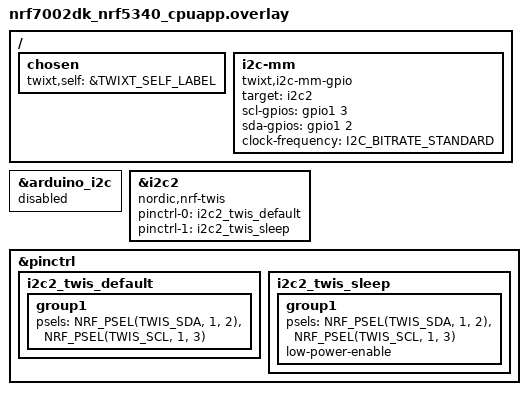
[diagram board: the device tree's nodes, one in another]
/*
 * Copyright (c) 2026 Christoph Jans <jans.christoph@gmail.com>
 *
 * SPDX-License-Identifier: Apache-2.0
 */

/* A board on an nRF7002 DK (-DMCU=b): the bus on the Arduino SDA P1.02, SCL P1.03, at the DK's
 * 1.8 V. TWIS2 is the target; the controller is software on the same pins (twixt,i2c-mm-gpio),
 * since the TWIM cannot detect lost arbitration. TWIM1 (arduino_i2c) has the same pins and is
 * off. The log is on the DK's VCOM.
 */

#include <zephyr/dt-bindings/i2c/i2c.h>

/ {
	chosen {
		twixt,self = &TWIXT_SELF_LABEL;
	};

	i2c-mm {
		compatible = "twixt,i2c-mm-gpio";
		target = <&i2c2>;
		scl-gpios = <&gpio1 3 0>;
		sda-gpios = <&gpio1 2 0>;
		clock-frequency = <I2C_BITRATE_STANDARD>;
		#address-cells = <1>;
		#size-cells = <0>;

#include "../twixt_mcus.dtsi"
	};
};

&arduino_i2c {
	status = "disabled";
};

&i2c2 {
	compatible = "nordic,nrf-twis";
	status = "okay";
	pinctrl-0 = <&i2c2_twis_default>;
	pinctrl-1 = <&i2c2_twis_sleep>;
	pinctrl-names = "default", "sleep";
};

&pinctrl {
	i2c2_twis_default: i2c2_twis_default {
		group1 {
			psels = <NRF_PSEL(TWIS_SDA, 1, 2)>,
				<NRF_PSEL(TWIS_SCL, 1, 3)>;
		};
	};

	i2c2_twis_sleep: i2c2_twis_sleep {
		group1 {
			psels = <NRF_PSEL(TWIS_SDA, 1, 2)>,
				<NRF_PSEL(TWIS_SCL, 1, 3)>;
			low-power-enable;
		};
	};
};
